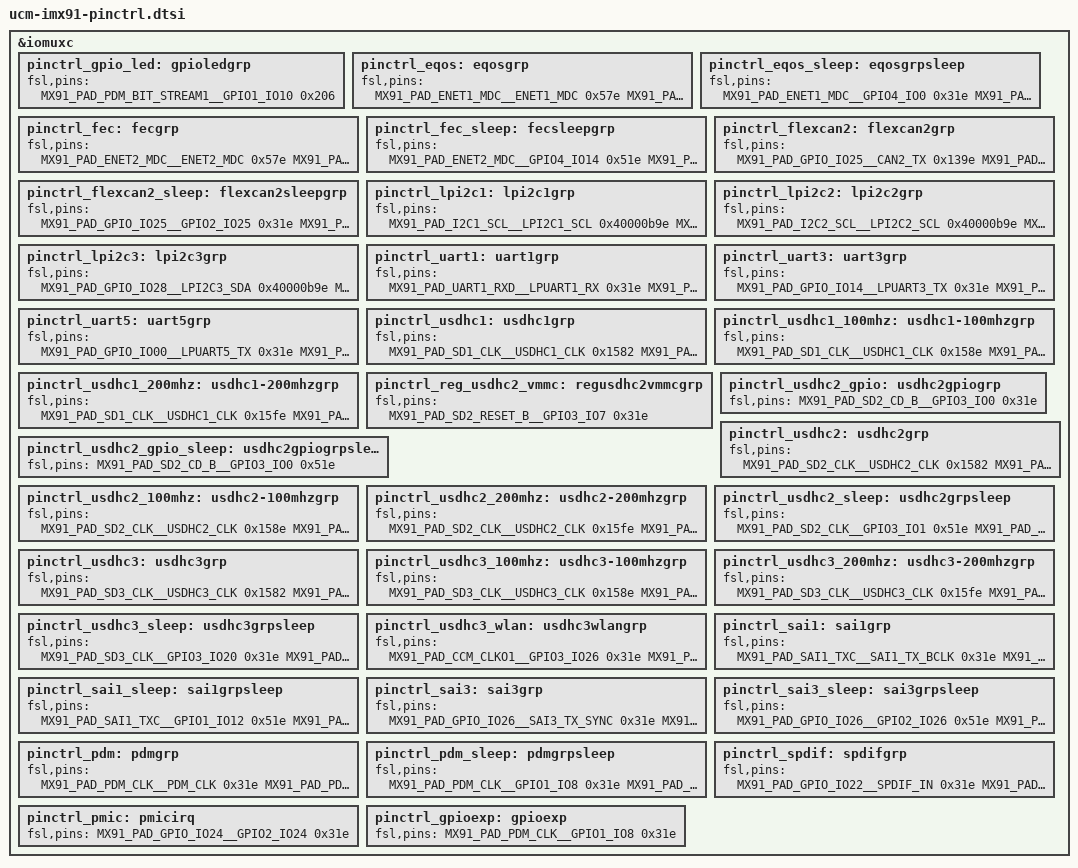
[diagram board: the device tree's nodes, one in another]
// SPDX-License-Identifier: (GPL-2.0+ OR MIT)
/*
 * Copyright 2026 CompuLab Ltd.
 */

&iomuxc {
	pinctrl_gpio_led: gpioledgrp {
		fsl,pins = <
			MX91_PAD_PDM_BIT_STREAM1__GPIO1_IO10	0x206
		>;
	};

	pinctrl_eqos: eqosgrp {
		fsl,pins = <
			MX91_PAD_ENET1_MDC__ENET1_MDC			0x57e
			MX91_PAD_ENET1_MDIO__ENET_QOS_MDIO			0x57e
			MX91_PAD_ENET1_RD0__ENET_QOS_RGMII_RD0			0x57e
			MX91_PAD_ENET1_RD1__ENET_QOS_RGMII_RD1			0x57e
			MX91_PAD_ENET1_RD2__ENET_QOS_RGMII_RD2			0x57e
			MX91_PAD_ENET1_RD3__ENET_QOS_RGMII_RD3			0x57e
			MX91_PAD_ENET1_RXC__ENET_QOS_RGMII_RXC	0x5fe
			MX91_PAD_ENET1_RX_CTL__ENET_QOS_RGMII_RX_CTL		0x57e
			MX91_PAD_ENET1_TD0__ENET_QOS_RGMII_TD0			0x57e
			MX91_PAD_ENET1_TD1__ENET1_RGMII_TD1			0x57e
			MX91_PAD_ENET1_TD2__ENET_QOS_RGMII_TD2			0x57e
			MX91_PAD_ENET1_TD3__ENET_QOS_RGMII_TD3			0x57e
			MX91_PAD_ENET1_TXC__CCM_ENET_QOS_CLOCK_GENERATE_TX_CLK	0x5fe
			MX91_PAD_ENET1_TX_CTL__ENET_QOS_RGMII_TX_CTL		0x57e
			MX91_PAD_GPIO_IO06__GPIO2_IO6				0x31e
		>;
	};

	pinctrl_eqos_sleep: eqosgrpsleep {
		fsl,pins = <
			MX91_PAD_ENET1_MDC__GPIO4_IO0				0x31e
			MX91_PAD_ENET1_MDIO__GPIO4_IO1				0x31e
			MX91_PAD_ENET1_RD0__GPIO4_IO10                          0x31e
			MX91_PAD_ENET1_RD1__GPIO4_IO11				0x31e
			MX91_PAD_ENET1_RD2__GPIO4_IO12				0x31e
			MX91_PAD_ENET1_RD3__GPIO4_IO13				0x31e
			MX91_PAD_ENET1_RXC__GPIO4_IO9                          0x31e
			MX91_PAD_ENET1_RX_CTL__GPIO4_IO8			0x31e
			MX91_PAD_ENET1_TD0__GPIO4_IO5                          0x31e
			MX91_PAD_ENET1_TD1__GPIO4_IO4                          0x31e
			MX91_PAD_ENET1_TD2__GPIO4_IO3				0x31e
			MX91_PAD_ENET1_TD3__GPIO4_IO2				0x31e
			MX91_PAD_ENET1_TXC__GPIO4_IO7                          0x31e
			MX91_PAD_ENET1_TX_CTL__GPIO4_IO6                       0x31e
		>;
	};

	pinctrl_fec: fecgrp {
		fsl,pins = <
			MX91_PAD_ENET2_MDC__ENET2_MDC			0x57e
			MX91_PAD_ENET2_MDIO__ENET2_MDIO			0x57e
			MX91_PAD_ENET2_RD0__ENET2_RGMII_RD0		0x57e
			MX91_PAD_ENET2_RD1__ENET2_RGMII_RD1		0x57e
			MX91_PAD_ENET2_RD2__ENET2_RGMII_RD2		0x57e
			MX91_PAD_ENET2_RD3__ENET2_RGMII_RD3		0x57e
			MX91_PAD_ENET2_RXC__ENET2_RGMII_RXC		0x5fe
			MX91_PAD_ENET2_RX_CTL__ENET2_RGMII_RX_CTL	0x57e
			MX91_PAD_ENET2_TD0__ENET2_RGMII_TD0		0x57e
			MX91_PAD_ENET2_TD1__ENET2_RGMII_TD1		0x57e
			MX91_PAD_ENET2_TD2__ENET2_RGMII_TD2		0x57e
			MX91_PAD_ENET2_TD3__ENET2_RGMII_TD3		0x57e
			MX91_PAD_ENET2_TXC__ENET2_RGMII_TXC		0x5fe
			MX91_PAD_ENET2_TX_CTL__ENET2_RGMII_TX_CTL	0x57e
		>;
	};

	pinctrl_fec_sleep: fecsleepgrp {
		fsl,pins = <
			MX91_PAD_ENET2_MDC__GPIO4_IO14			0x51e
			MX91_PAD_ENET2_MDIO__GPIO4_IO15			0x51e
			MX91_PAD_ENET2_RD0__GPIO4_IO24			0x51e
			MX91_PAD_ENET2_RD1__GPIO4_IO25			0x51e
			MX91_PAD_ENET2_RD2__GPIO4_IO26			0x51e
			MX91_PAD_ENET2_RD3__GPIO4_IO27			0x51e
			MX91_PAD_ENET2_RXC__GPIO4_IO23                  0x51e
			MX91_PAD_ENET2_RX_CTL__GPIO4_IO22		0x51e
			MX91_PAD_ENET2_TD0__GPIO4_IO19			0x51e
			MX91_PAD_ENET2_TD1__GPIO4_IO18			0x51e
			MX91_PAD_ENET2_TD2__GPIO4_IO17			0x51e
			MX91_PAD_ENET2_TD3__GPIO4_IO16			0x51e
			MX91_PAD_ENET2_TXC__GPIO4_IO21                  0x51e
			MX91_PAD_ENET2_TX_CTL__GPIO4_IO20               0x51e
		>;
	};

	pinctrl_flexcan2: flexcan2grp {
		fsl,pins = <
			MX91_PAD_GPIO_IO25__CAN2_TX	0x139e
			MX91_PAD_GPIO_IO27__CAN2_RX	0x139e
		>;
	};
	pinctrl_flexcan2_sleep: flexcan2sleepgrp {
		fsl,pins = <
			MX91_PAD_GPIO_IO25__GPIO2_IO25  0x31e
			MX91_PAD_GPIO_IO27__GPIO2_IO27	0x31e
		>;
	};

	pinctrl_lpi2c1: lpi2c1grp {
		fsl,pins = <
			MX91_PAD_I2C1_SCL__LPI2C1_SCL		0x40000b9e
			MX91_PAD_I2C1_SDA__LPI2C1_SDA		0x40000b9e
		>;
	};

	pinctrl_lpi2c2: lpi2c2grp {
		fsl,pins = <
			MX91_PAD_I2C2_SCL__LPI2C2_SCL		0x40000b9e
			MX91_PAD_I2C2_SDA__LPI2C2_SDA		0x40000b9e
		>;
	};

	pinctrl_lpi2c3: lpi2c3grp {
		fsl,pins = <
			MX91_PAD_GPIO_IO28__LPI2C3_SDA		0x40000b9e
			MX91_PAD_GPIO_IO29__LPI2C3_SCL		0x40000b9e
		>;
	};

	pinctrl_uart1: uart1grp {
		fsl,pins = <
			MX91_PAD_UART1_RXD__LPUART1_RX		0x31e
			MX91_PAD_UART1_TXD__LPUART1_TX		0x31e
		>;
	};

	pinctrl_uart3: uart3grp {
		fsl,pins = <
			MX91_PAD_GPIO_IO14__LPUART3_TX		0x31e
			MX91_PAD_GPIO_IO15__LPUART3_RX          0x31e
		>;
	};

	pinctrl_uart5: uart5grp {
		fsl,pins = <
			MX91_PAD_GPIO_IO00__LPUART5_TX		0x31e
			MX91_PAD_GPIO_IO01__LPUART5_RX		0x31e
			MX91_PAD_GPIO_IO02__LPUART5_CTS_B	0x31e
			MX91_PAD_GPIO_IO03__LPUART5_RTS_B	0x31e
		>;
	};

	pinctrl_usdhc1: usdhc1grp {
		fsl,pins = <
			MX91_PAD_SD1_CLK__USDHC1_CLK		0x1582
			MX91_PAD_SD1_CMD__USDHC1_CMD		0x1382
			MX91_PAD_SD1_DATA0__USDHC1_DATA0	0x1382
			MX91_PAD_SD1_DATA1__USDHC1_DATA1	0x1382
			MX91_PAD_SD1_DATA2__USDHC1_DATA2	0x1382
			MX91_PAD_SD1_DATA3__USDHC1_DATA3	0x1382
			MX91_PAD_SD1_DATA4__USDHC1_DATA4	0x1382
			MX91_PAD_SD1_DATA5__USDHC1_DATA5	0x1382
			MX91_PAD_SD1_DATA6__USDHC1_DATA6	0x1382
			MX91_PAD_SD1_DATA7__USDHC1_DATA7	0x1382
			MX91_PAD_SD1_STROBE__USDHC1_STROBE	0x1582
		>;
	};

	pinctrl_usdhc1_100mhz: usdhc1-100mhzgrp {
		fsl,pins = <
			MX91_PAD_SD1_CLK__USDHC1_CLK		0x158e
			MX91_PAD_SD1_CMD__USDHC1_CMD		0x138e
			MX91_PAD_SD1_DATA0__USDHC1_DATA0	0x138e
			MX91_PAD_SD1_DATA1__USDHC1_DATA1	0x138e
			MX91_PAD_SD1_DATA2__USDHC1_DATA2	0x138e
			MX91_PAD_SD1_DATA3__USDHC1_DATA3	0x138e
			MX91_PAD_SD1_DATA4__USDHC1_DATA4	0x138e
			MX91_PAD_SD1_DATA5__USDHC1_DATA5	0x138e
			MX91_PAD_SD1_DATA6__USDHC1_DATA6	0x138e
			MX91_PAD_SD1_DATA7__USDHC1_DATA7	0x138e
			MX91_PAD_SD1_STROBE__USDHC1_STROBE	0x158e
		>;
	};

	pinctrl_usdhc1_200mhz: usdhc1-200mhzgrp {
		fsl,pins = <
			MX91_PAD_SD1_CLK__USDHC1_CLK		0x15fe
			MX91_PAD_SD1_CMD__USDHC1_CMD		0x13fe
			MX91_PAD_SD1_DATA0__USDHC1_DATA0	0x13fe
			MX91_PAD_SD1_DATA1__USDHC1_DATA1	0x13fe
			MX91_PAD_SD1_DATA2__USDHC1_DATA2	0x13fe
			MX91_PAD_SD1_DATA3__USDHC1_DATA3	0x13fe
			MX91_PAD_SD1_DATA4__USDHC1_DATA4	0x13fe
			MX91_PAD_SD1_DATA5__USDHC1_DATA5	0x13fe
			MX91_PAD_SD1_DATA6__USDHC1_DATA6	0x13fe
			MX91_PAD_SD1_DATA7__USDHC1_DATA7	0x13fe
			MX91_PAD_SD1_STROBE__USDHC1_STROBE	0x15fe
		>;
	};

	pinctrl_reg_usdhc2_vmmc: regusdhc2vmmcgrp {
		fsl,pins = <
			MX91_PAD_SD2_RESET_B__GPIO3_IO7	0x31e
		>;
	};

	pinctrl_usdhc2_gpio: usdhc2gpiogrp {
		fsl,pins = <
			MX91_PAD_SD2_CD_B__GPIO3_IO0		0x31e
		>;
	};

	pinctrl_usdhc2_gpio_sleep: usdhc2gpiogrpsleep {
		fsl,pins = <
			MX91_PAD_SD2_CD_B__GPIO3_IO0		0x51e
		>;
	};

	pinctrl_usdhc2: usdhc2grp {
		fsl,pins = <
			MX91_PAD_SD2_CLK__USDHC2_CLK		0x1582
			MX91_PAD_SD2_CMD__USDHC2_CMD		0x1382
			MX91_PAD_SD2_DATA0__USDHC2_DATA0	0x1382
			MX91_PAD_SD2_DATA1__USDHC2_DATA1	0x1382
			MX91_PAD_SD2_DATA2__USDHC2_DATA2	0x1382
			MX91_PAD_SD2_DATA3__USDHC2_DATA3	0x1382
			MX91_PAD_SD2_VSELECT__USDHC2_VSELECT	0x51e
		>;
	};

	pinctrl_usdhc2_100mhz: usdhc2-100mhzgrp {
		fsl,pins = <
			MX91_PAD_SD2_CLK__USDHC2_CLK		0x158e
			MX91_PAD_SD2_CMD__USDHC2_CMD		0x138e
			MX91_PAD_SD2_DATA0__USDHC2_DATA0	0x138e
			MX91_PAD_SD2_DATA1__USDHC2_DATA1	0x138e
			MX91_PAD_SD2_DATA2__USDHC2_DATA2	0x138e
			MX91_PAD_SD2_DATA3__USDHC2_DATA3	0x138e
			MX91_PAD_SD2_VSELECT__USDHC2_VSELECT	0x51e
		>;
	};

	pinctrl_usdhc2_200mhz: usdhc2-200mhzgrp {
		fsl,pins = <
			MX91_PAD_SD2_CLK__USDHC2_CLK		0x15fe
			MX91_PAD_SD2_CMD__USDHC2_CMD		0x13fe
			MX91_PAD_SD2_DATA0__USDHC2_DATA0	0x13fe
			MX91_PAD_SD2_DATA1__USDHC2_DATA1	0x13fe
			MX91_PAD_SD2_DATA2__USDHC2_DATA2	0x13fe
			MX91_PAD_SD2_DATA3__USDHC2_DATA3	0x13fe
			MX91_PAD_SD2_VSELECT__USDHC2_VSELECT	0x51e
		>;
	};

	pinctrl_usdhc2_sleep: usdhc2grpsleep {
		fsl,pins = <
			MX91_PAD_SD2_CLK__GPIO3_IO1            0x51e
			MX91_PAD_SD2_CMD__GPIO3_IO2		0x51e
			MX91_PAD_SD2_DATA0__GPIO3_IO3		0x51e
			MX91_PAD_SD2_DATA1__GPIO3_IO4		0x51e
			MX91_PAD_SD2_DATA2__GPIO3_IO5		0x51e
			MX91_PAD_SD2_DATA3__GPIO3_IO6		0x51e
			MX91_PAD_SD2_VSELECT__GPIO3_IO19	0x51e
		>;
	};

	pinctrl_usdhc3: usdhc3grp {
		fsl,pins = <
			MX91_PAD_SD3_CLK__USDHC3_CLK		0x1582
			MX91_PAD_SD3_CMD__USDHC3_CMD		0x1382
			MX91_PAD_SD3_DATA0__USDHC3_DATA0	0x1382
			MX91_PAD_SD3_DATA1__USDHC3_DATA1	0x1382
			MX91_PAD_SD3_DATA2__USDHC3_DATA2	0x1382
			MX91_PAD_SD3_DATA3__USDHC3_DATA3	0x1382
		>;
	};

	pinctrl_usdhc3_100mhz: usdhc3-100mhzgrp {
		fsl,pins = <
			MX91_PAD_SD3_CLK__USDHC3_CLK		0x158e
			MX91_PAD_SD3_CMD__USDHC3_CMD		0x138e
			MX91_PAD_SD3_DATA0__USDHC3_DATA0	0x138e
			MX91_PAD_SD3_DATA1__USDHC3_DATA1	0x138e
			MX91_PAD_SD3_DATA2__USDHC3_DATA2	0x138e
			MX91_PAD_SD3_DATA3__USDHC3_DATA3	0x138e
		>;
	};

	pinctrl_usdhc3_200mhz: usdhc3-200mhzgrp {
		fsl,pins = <
			MX91_PAD_SD3_CLK__USDHC3_CLK		0x15fe
			MX91_PAD_SD3_CMD__USDHC3_CMD		0x13fe
			MX91_PAD_SD3_DATA0__USDHC3_DATA0	0x13fe
			MX91_PAD_SD3_DATA1__USDHC3_DATA1	0x13fe
			MX91_PAD_SD3_DATA2__USDHC3_DATA2	0x13fe
			MX91_PAD_SD3_DATA3__USDHC3_DATA3	0x13fe
		>;
	};

	pinctrl_usdhc3_sleep: usdhc3grpsleep {
		fsl,pins = <
			MX91_PAD_SD3_CLK__GPIO3_IO20		0x31e
			MX91_PAD_SD3_CMD__GPIO3_IO21		0x31e
			MX91_PAD_SD3_DATA0__GPIO3_IO22		0x31e
			MX91_PAD_SD3_DATA1__GPIO3_IO23		0x31e
			MX91_PAD_SD3_DATA2__GPIO3_IO24		0x31e
			MX91_PAD_SD3_DATA3__GPIO3_IO25		0x31e
		>;
	};

	pinctrl_usdhc3_wlan: usdhc3wlangrp {
		fsl,pins = <
			MX91_PAD_CCM_CLKO1__GPIO3_IO26			0x31e
			MX91_PAD_GPIO_IO07__GPIO2_IO7			0x31e
		>;
	};

	pinctrl_sai1: sai1grp {
		fsl,pins = <
			MX91_PAD_SAI1_TXC__SAI1_TX_BCLK			0x31e
			MX91_PAD_SAI1_TXFS__SAI1_TX_SYNC		0x31e
			MX91_PAD_SAI1_TXD0__SAI1_TX_DATA0		0x31e
			MX91_PAD_SAI1_RXD0__SAI1_RX_DATA0		0x31e
		>;
	};

	pinctrl_sai1_sleep: sai1grpsleep {
		fsl,pins = <
			MX91_PAD_SAI1_TXC__GPIO1_IO12                   0x51e
			MX91_PAD_SAI1_TXFS__GPIO1_IO11			0x51e
			MX91_PAD_SAI1_TXD0__GPIO1_IO13			0x51e
			MX91_PAD_SAI1_RXD0__GPIO1_IO14			0x51e
		>;
	};

	pinctrl_sai3: sai3grp {
		fsl,pins = <
			MX91_PAD_GPIO_IO26__SAI3_TX_SYNC		0x31e
			MX91_PAD_GPIO_IO16__SAI3_TX_BCLK		0x31e
			MX91_PAD_GPIO_IO17__SAI3_MCLK			0x31e
			MX91_PAD_GPIO_IO19__SAI3_TX_DATA0		0x31e
			MX91_PAD_GPIO_IO20__SAI3_RX_DATA0		0x31e
		>;
	};

	pinctrl_sai3_sleep: sai3grpsleep {
		fsl,pins = <
			MX91_PAD_GPIO_IO26__GPIO2_IO26			0x51e
			MX91_PAD_GPIO_IO16__GPIO2_IO16			0x51e
			MX91_PAD_GPIO_IO17__GPIO2_IO17			0x51e
			MX91_PAD_GPIO_IO19__GPIO2_IO19			0x51e
			MX91_PAD_GPIO_IO20__GPIO2_IO20			0x51e
		>;
	};

	pinctrl_pdm: pdmgrp {
		fsl,pins = <
			MX91_PAD_PDM_CLK__PDM_CLK			0x31e
			MX91_PAD_PDM_BIT_STREAM0__PDM_BIT_STREAM0	0x31e
			MX91_PAD_PDM_BIT_STREAM1__PDM_BIT_STREAM1	0x31e
		>;
	};

	pinctrl_pdm_sleep: pdmgrpsleep {
		fsl,pins = <
			MX91_PAD_PDM_CLK__GPIO1_IO8			0x31e
			MX91_PAD_PDM_BIT_STREAM0__GPIO1_IO9		0x31e
			MX91_PAD_PDM_BIT_STREAM1__GPIO1_IO10		0x31e
		>;
	};

	pinctrl_spdif: spdifgrp {
		fsl,pins = <
			MX91_PAD_GPIO_IO22__SPDIF_IN		0x31e
			MX91_PAD_GPIO_IO23__SPDIF_OUT		0x31e
		>;
	};

	pinctrl_pmic: pmicirq {
		fsl,pins = <
			MX91_PAD_GPIO_IO24__GPIO2_IO24		0x31e
		>;
	};

	pinctrl_gpioexp: gpioexp {
		fsl,pins = <
			MX91_PAD_PDM_CLK__GPIO1_IO8			0x31e
		>;
	};
};
